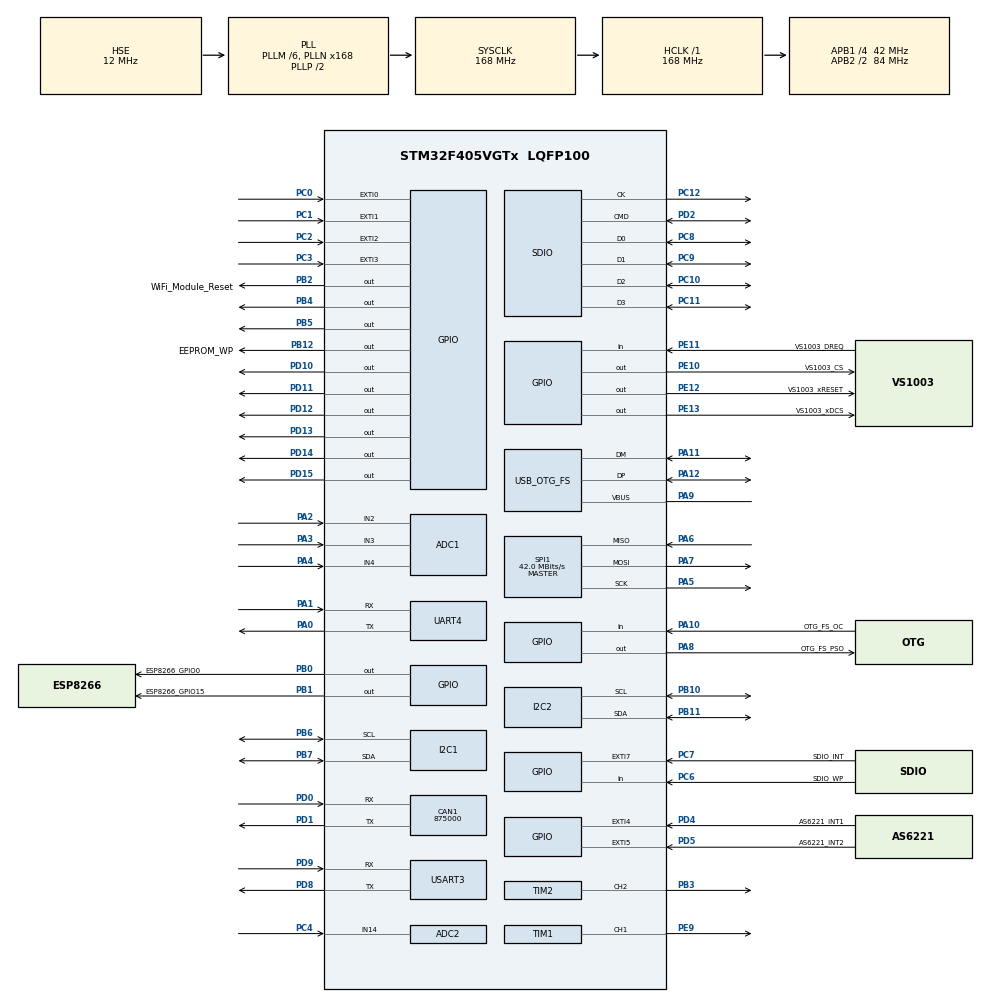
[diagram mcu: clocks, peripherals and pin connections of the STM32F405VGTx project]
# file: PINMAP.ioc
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ADC1.Channel-0\#ChannelRegularConversion=ADC_CHANNEL_3
ADC1.ClockPrescaler=ADC_CLOCK_SYNC_PCLK_DIV4
ADC1.NbrOfConversionFlag=1
ADC1.Rank-0\#ChannelRegularConversion=1
ADC1.SamplingTime-0\#ChannelRegularConversion=ADC_SAMPLETIME_3CYCLES
ADC1.master=1
ADC2.Channel-2\#ChannelRegularConversion=ADC_CHANNEL_14
ADC2.ClockPrescaler=ADC_CLOCK_SYNC_PCLK_DIV4
ADC2.NbrOfConversionFlag=1
ADC2.Rank-2\#ChannelRegularConversion=1
ADC2.SamplingTime-2\#ChannelRegularConversion=ADC_SAMPLETIME_3CYCLES
CAN1.CalculateBaudRate=875000
CAN1.CalculateTimeBit=1142
CAN1.CalculateTimeQuantum=380.95238095238096
Mcu.Family=STM32F4
Mcu.Name=STM32F405VGTx
Mcu.Package=LQFP100
NVIC.OTG_FS_IRQn=true\:0\:0\:false\:false\:true\:false\:true\:true
NVIC.PriorityGroup=NVIC_PRIORITYGROUP_4
PA0-WKUP.Mode=Asynchronous
PA0-WKUP.Signal=UART4_TX
PA1.Mode=Asynchronous
PA1.Signal=UART4_RX
PA10.GPIO_Label=OTG_FS_OC
PA10.Signal=GPIO_Input
PA11.Mode=Host_Only
PA11.Signal=USB_OTG_FS_DM
PA12.Mode=Host_Only
PA12.Signal=USB_OTG_FS_DP
PA13.Mode=Serial_Wire
PA13.Signal=SYS_JTMS-SWDIO
PA14.Mode=Serial_Wire
PA14.Signal=SYS_JTCK-SWCLK
PA2.Signal=ADCx_IN2
PA3.Signal=ADCx_IN3
PA4.Signal=ADCx_IN4
PA5.Mode=Full_Duplex_Master
PA5.Signal=SPI1_SCK
PA6.Mode=Full_Duplex_Master
PA6.Signal=SPI1_MISO
PA7.Mode=Full_Duplex_Master
PA7.Signal=SPI1_MOSI
PA8.GPIO_Label=OTG_FS_PSO
PA8.Signal=GPIO_Output
PA9.Mode=Activate_VBUS
PA9.Signal=USB_OTG_FS_VBUS
PB0.GPIO_Label=ESP8266_GPIO0
PB0.Signal=GPIO_Output
PB1.GPIO_Label=ESP8266_GPIO15
PB1.Signal=GPIO_Output
PB10.Mode=I2C
PB10.Signal=I2C2_SCL
PB11.Mode=I2C
PB11.Signal=I2C2_SDA
PB12.GPIO_Label=EEPROM_WP
PB12.Signal=GPIO_Output
PB2.GPIO_Label=WiFi_Module_Reset
PB2.Signal=GPIO_Output
PB3.Signal=S_TIM2_CH2
PB4.Signal=GPIO_Output
PB5.Signal=GPIO_Output
PB6.Mode=I2C
PB6.Signal=I2C1_SCL
PB7.Mode=I2C
PB7.Signal=I2C1_SDA
PC0.Signal=GPXTI0
PC1.Signal=GPXTI1
PC10.Mode=SD_4_bits_Wide_bus
PC10.Signal=SDIO_D2
PC11.Mode=SD_4_bits_Wide_bus
PC11.Signal=SDIO_D3
PC12.Mode=SD_4_bits_Wide_bus
PC12.Signal=SDIO_CK
PC2.Signal=GPXTI2
PC3.Signal=GPXTI3
PC4.Signal=ADCx_IN14
PC6.GPIO_Label=SDIO_WP
PC6.Signal=GPIO_Input
PC7.GPIO_Label=SDIO_INT
PC7.Signal=GPXTI7
PC8.Mode=SD_4_bits_Wide_bus
PC8.Signal=SDIO_D0
PC9.Mode=SD_4_bits_Wide_bus
PC9.Signal=SDIO_D1
PD0.Mode=CAN_Activate
PD0.Signal=CAN1_RX
PD1.Mode=CAN_Activate
PD1.Signal=CAN1_TX
PD10.Signal=GPIO_Output
PD11.Signal=GPIO_Output
PD12.Signal=GPIO_Output
PD13.Signal=GPIO_Output
PD14.Signal=GPIO_Output
PD15.Signal=GPIO_Output
PD2.Mode=SD_4_bits_Wide_bus
PD2.Signal=SDIO_CMD
PD4.GPIO_Label=AS6221_INT1
PD4.Signal=GPXTI4
PD5.GPIO_Label=AS6221_INT2
PD5.Signal=GPXTI5
PD8.Mode=Asynchronous
PD8.Signal=USART3_TX
PD9.Mode=Asynchronous
PD9.Signal=USART3_RX
PE10.GPIO_Label=VS1003_CS
PE10.Signal=GPIO_Output
PE11.GPIO_Label=VS1003_DREQ
PE11.Signal=GPIO_Input
PE12.GPIO_Label=VS1003_xRESET
PE12.Signal=GPIO_Output
PE13.GPIO_Label=VS1003_xDCS
PE13.Signal=GPIO_Output
PE9.Signal=S_TIM1_CH1
PH0-OSC_IN.Mode=HSE-External-Oscillator
PH0-OSC_IN.Signal=RCC_OSC_IN
PH1-OSC_OUT.Mode=HSE-External-Oscillator
PH1-OSC_OUT.Signal=RCC_OSC_OUT
ProjectManager.HeapSize=0x200
ProjectManager.StackSize=0x400
ProjectManager.TargetToolchain=STM32CubeIDE
RCC.48MHZClocksFreq_Value=48000000
RCC.AHBFreq_Value=168000000
RCC.APB1CLKDivider=RCC_HCLK_DIV4
RCC.APB1Freq_Value=42000000
RCC.APB1TimFreq_Value=84000000
RCC.APB2CLKDivider=RCC_HCLK_DIV2
RCC.APB2Freq_Value=84000000
RCC.APB2TimFreq_Value=168000000
RCC.CortexFreq_Value=168000000
RCC.HCLKFreq_Value=168000000
RCC.HSE_VALUE=12000000
RCC.HSI_VALUE=16000000
RCC.LSE_VALUE=32768
RCC.PLLM=6
RCC.PLLN=168
RCC.PLLQ=7
RCC.SYSCLKFreq_VALUE=168000000
RCC.SYSCLKSource=RCC_SYSCLKSOURCE_PLLCLK
RCC.VCOOutputFreq_Value=336000000
SH.ADCx_IN14.0=ADC2_IN14,IN14
SH.ADCx_IN2.0=ADC1_IN2,IN2
SH.ADCx_IN3.0=ADC1_IN3,IN3
SH.ADCx_IN4.0=ADC1_IN4,IN4
SH.S_TIM1_CH1.0=TIM1_CH1,PWM Generation1 CH1
SH.S_TIM2_CH2.0=TIM2_CH2,PWM Generation2 CH2
SPI1.CalculateBaudRate=42.0 MBits/s
SPI1.Direction=SPI_DIRECTION_2LINES
SPI1.Mode=SPI_MODE_MASTER
SPI1.VirtualType=VM_MASTER
TIM1.Channel-PWM\ Generation1\ CH1=TIM_CHANNEL_1
TIM2.Channel-PWM\ Generation2\ CH2=TIM_CHANNEL_2
UART4.VirtualMode=Asynchronous
USART3.VirtualMode=VM_ASYNC
USB_HOST.USBH_HandleTypeDef-MSC_FS=hUsbHostFS
USB_HOST.VirtualModeFS=Msc
USB_OTG_FS.VirtualMode=Host_Only
USB_OTG_FS.phy_itface=HCD_PHY_EMBEDDED
VP_FATFS_VS_USB.Mode=USB
VP_TIM1_VS_ClockSourceINT.Mode=Internal
VP_TIM2_VS_ClockSourceINT.Mode=Internal
VP_TIM3_VS_ClockSourceINT.Mode=Internal
VP_USB_HOST_VS_USB_HOST_MSC_FS.Mode=MSC_FS
board=custom

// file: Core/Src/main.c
/* USER CODE BEGIN Header */
/**
  ******************************************************************************
  * @file           : main.c
  * @brief          : Main program body
  ******************************************************************************
  * @attention
  *
  * Copyright (c) 2025 STMicroelectronics.
  * All rights reserved.
  *
  * This software is licensed under terms that can be found in the LICENSE file
  * in the root directory of this software component.
  * If no LICENSE file comes with this software, it is provided AS-IS.
  *
  ******************************************************************************
  */
/* USER CODE END Header */
#include "main.h"
#include "adc.h"
#include "can.h"
#include "fatfs.h"
#include "i2c.h"
#include "sdio.h"
#include "spi.h"
#include "tim.h"
#include "usart.h"
#include "usb_host.h"
#include "gpio.h"

void SystemClock_Config(void);
void MX_USB_HOST_Process(void);

int main(void)
{

  /* MCU Configuration--------------------------------------------------------*/

  /* Reset of all peripherals, Initializes the Flash interface and the Systick. */
  HAL_Init();

  /* Configure the system clock */
  SystemClock_Config();

  /* Initialize all configured peripherals */
  MX_GPIO_Init();
  MX_ADC1_Init();
  MX_ADC2_Init();
  MX_CAN1_Init();
  MX_I2C1_Init();
  MX_I2C2_Init();
  MX_SDIO_SD_Init();
  MX_SPI1_Init();
  MX_TIM1_Init();
  MX_TIM2_Init();
  MX_TIM3_Init();
  MX_UART4_Init();
  MX_USART3_UART_Init();
  MX_FATFS_Init();
  MX_USB_HOST_Init();

  /* Infinite loop */
  /* USER CODE BEGIN WHILE */
  while (1)
  {
	 HAL_GPIO_TogglePin(GPIOB, GPIO_PIN_4);
	 HAL_Delay(1000);
	 HAL_GPIO_TogglePin(GPIOB, GPIO_PIN_5);
	 HAL_Delay(1000);
    /* USER CODE END WHILE */
    MX_USB_HOST_Process();

  }
}

void SystemClock_Config(void)
{
  RCC_OscInitTypeDef RCC_OscInitStruct = {0};
  RCC_ClkInitTypeDef RCC_ClkInitStruct = {0};

  /** Configure the main internal regulator output voltage
  */
  __HAL_RCC_PWR_CLK_ENABLE();
  __HAL_PWR_VOLTAGESCALING_CONFIG(PWR_REGULATOR_VOLTAGE_SCALE1);

  /** Initializes the RCC Oscillators according to the specified parameters
  * in the RCC_OscInitTypeDef structure.
  */
  RCC_OscInitStruct.OscillatorType = RCC_OSCILLATORTYPE_HSE;
  RCC_OscInitStruct.HSEState = RCC_HSE_ON;
  RCC_OscInitStruct.PLL.PLLState = RCC_PLL_ON;
  RCC_OscInitStruct.PLL.PLLSource = RCC_PLLSOURCE_HSE;
  RCC_OscInitStruct.PLL.PLLM = 6;
  RCC_OscInitStruct.PLL.PLLN = 168;
  RCC_OscInitStruct.PLL.PLLP = RCC_PLLP_DIV2;
  RCC_OscInitStruct.PLL.PLLQ = 7;
  if (HAL_RCC_OscConfig(&RCC_OscInitStruct) != HAL_OK)
  {
    Error_Handler();
  }

  /** Initializes the CPU, AHB and APB buses clocks
  */
  RCC_ClkInitStruct.ClockType = RCC_CLOCKTYPE_HCLK|RCC_CLOCKTYPE_SYSCLK
                              |RCC_CLOCKTYPE_PCLK1|RCC_CLOCKTYPE_PCLK2;
  RCC_ClkInitStruct.SYSCLKSource = RCC_SYSCLKSOURCE_PLLCLK;
  RCC_ClkInitStruct.AHBCLKDivider = RCC_SYSCLK_DIV1;
  RCC_ClkInitStruct.APB1CLKDivider = RCC_HCLK_DIV4;
  RCC_ClkInitStruct.APB2CLKDivider = RCC_HCLK_DIV2;

  if (HAL_RCC_ClockConfig(&RCC_ClkInitStruct, FLASH_LATENCY_5) != HAL_OK)
  {
    Error_Handler();
  }
}

void Error_Handler(void)
{
  __disable_irq();
  while (1)
  {
  }
}
